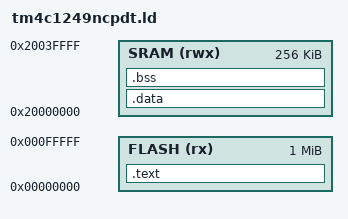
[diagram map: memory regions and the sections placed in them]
/* Linker Script for TM4C1249NPCDT */

MEMORY
{
    FLASH (rx) : ORIGIN = 0x00000000, LENGTH = 1M
    SRAM (rwx) : ORIGIN = 0x20000000, LENGTH = 256K
}

SECTIONS
{
    PROVIDE( _stack_ptr = ORIGIN(SRAM) + LENGTH(SRAM) );

    .text :
    {
        _text = .;
        KEEP(*(.isr_vector))
        *(.text*)
        *(.rodata*)
        *(.init*)
        *(.fini*)
        _etext = .;
    } > FLASH

    .data : AT(ADDR(.text) + SIZEOF(.text))
    {
        _data = .;
        *(vtable)
        *(.ARM.exidx*)
        *(.gnu.linkonce.armexidx.*)
        *(.data*)
        _edata = .;
    } > SRAM

    .bss :
    {
        _bss = .;
        *(.bss*)
        *(COMMON)
        _ebss = .;
    } > SRAM
}
